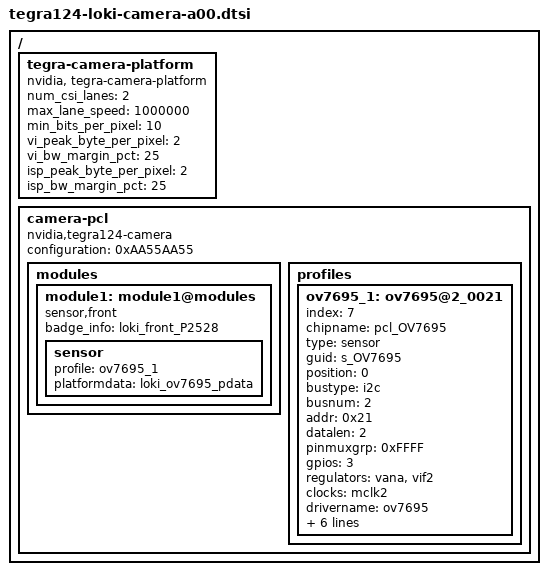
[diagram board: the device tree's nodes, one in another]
/*
 * Copyright (c) 2016, NVIDIA CORPORATION.  All rights reserved.
 *
 * This program is free software; you can redistribute it and/or modify it
 * under the terms and conditions of the GNU General Public License,
 * version 2, as published by the Free Software Foundation.
 *
 * This program is distributed in the hope it will be useful, but WITHOUT
 * ANY WARRANTY; without even the implied warranty of MERCHANTABILITY or
 * FITNESS FOR A PARTICULAR PURPOSE.  See the GNU General Public License for
 * more details.
 *
 * arch/arm/boot/dts/tegra124-platforms/tegra124-loki-camera-a00.dtsi
 */

#include <dt-bindings/media/camera.h>

/ {
	tegra-camera-platform {
		compatible = "nvidia, tegra-camera-platform";
		/**
		* Physical settings to calculate max ISO BW
		*
		* num_csi_lanes = <>;
		* Total number of CSI lanes when all cameras are active
		*
		* max_lane_speed = <>;
		* Max lane speed in Kbit/s
		*
		* min_bits_per_pixel = <>;
		* Min bits per pixel
		*
		* vi_peak_byte_per_pixel = <>;
		* Max byte per pixel for the VI ISO case
		*
		* vi_bw_margin_pct = <>;
		* Vi bandwidth margin in percentage
		*
		* isp_peak_byte_per_pixel = <>;
		* Max byte per pixel for the ISP ISO case
		*
		* isp_bw_margin_pct = <>;
		* Isp bandwidth margin in percentage
		*/
		num_csi_lanes = <2>;
		max_lane_speed = <1000000>;
		min_bits_per_pixel = <10>;
		vi_peak_byte_per_pixel = <2>;
		vi_bw_margin_pct = <25>;
		isp_peak_byte_per_pixel = <2>;
		isp_bw_margin_pct = <25>;
	};

	camera-pcl {
		compatible = "nvidia,tegra124-camera", "simple-bus";
		configuration = <0xAA55AA55>;

		modules {
			module1: module1@modules {
				compatible = "sensor,front";
				badge_info = "loki_front_P2528";

				sensor {
					profile = <&ov7695_1>;
					platformdata = "loki_ov7695_pdata";
				};
			};
		};

		profiles {
			ov7695_1: ov7695@2_0021 {
				index = <7>;
				chipname = "pcl_OV7695";
				type = "sensor";
				guid = "s_OV7695";
				position = <0>;
				bustype = "i2c";
				busnum = <2>;
				addr = <0x21>;
				datalen = <2>;
				pinmuxgrp = <0xFFFF>;
				gpios = <3>;
				regulators = "vana", "vif2";
				clocks = "mclk2";
				drivername = "ov7695";
				detect = <0x0002 0x300A 0xFFFF 0x7695>;
				devid = <0x7695>;
				poweron = <
					CAMERA_IND_CLK_SET(10000)
					CAMERA_GPIO_CLR(222)
					CAMERA_REGULATOR_ON(0)
					CAMERA_REGULATOR_ON(1)
					CAMERA_WAITMS(40)
					CAMERA_GPIO_SET(222)
					CAMERA_WAITMS(10)
					CAMERA_END
					>;
				poweroff = <
					CAMERA_IND_CLK_CLR
					CAMERA_GPIO_CLR(222)
					CAMERA_WAITUS(10)
					CAMERA_REGULATOR_OFF(1)
					CAMERA_REGULATOR_OFF(0)
					CAMERA_END
					>;
			};
		};
	};
};

